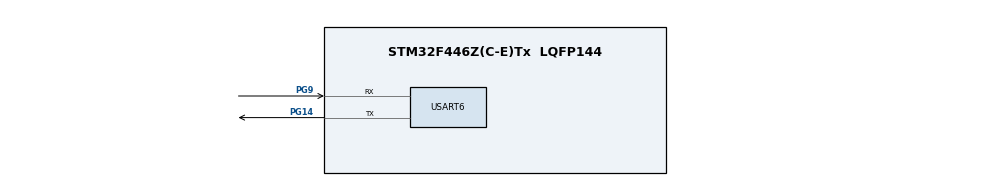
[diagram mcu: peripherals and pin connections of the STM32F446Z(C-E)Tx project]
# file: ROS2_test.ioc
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Dma.Request0=USART6_RX
Dma.Request1=USART6_TX
Dma.USART6_RX.0.Direction=DMA_PERIPH_TO_MEMORY
Dma.USART6_RX.0.FIFOMode=DMA_FIFOMODE_DISABLE
Dma.USART6_RX.0.Instance=DMA2_Stream1
Dma.USART6_RX.0.MemDataAlignment=DMA_MDATAALIGN_BYTE
Dma.USART6_RX.0.MemInc=DMA_MINC_ENABLE
Dma.USART6_RX.0.Mode=DMA_CIRCULAR
Dma.USART6_RX.0.PeriphDataAlignment=DMA_PDATAALIGN_BYTE
Dma.USART6_RX.0.PeriphInc=DMA_PINC_DISABLE
Dma.USART6_RX.0.Priority=DMA_PRIORITY_VERY_HIGH
Dma.USART6_TX.1.Direction=DMA_MEMORY_TO_PERIPH
Dma.USART6_TX.1.FIFOMode=DMA_FIFOMODE_DISABLE
Dma.USART6_TX.1.Instance=DMA2_Stream6
Dma.USART6_TX.1.MemDataAlignment=DMA_MDATAALIGN_BYTE
Dma.USART6_TX.1.MemInc=DMA_MINC_ENABLE
Dma.USART6_TX.1.Mode=DMA_NORMAL
Dma.USART6_TX.1.PeriphDataAlignment=DMA_PDATAALIGN_BYTE
Dma.USART6_TX.1.PeriphInc=DMA_PINC_DISABLE
Dma.USART6_TX.1.Priority=DMA_PRIORITY_VERY_HIGH
FREERTOS.Tasks01=defaultTask,24,3000,StartDefaultTask,Default,NULL,Dynamic,NULL,NULL
Mcu.Family=STM32F4
Mcu.Name=STM32F446Z(C-E)Tx
Mcu.Package=LQFP144
NVIC.DMA2_Stream1_IRQn=true\:5\:0\:false\:false\:true\:true\:false\:true\:true
NVIC.DMA2_Stream6_IRQn=true\:5\:0\:false\:false\:true\:true\:false\:true\:true
NVIC.PriorityGroup=NVIC_PRIORITYGROUP_4
NVIC.TIM1_UP_TIM10_IRQn=true\:15\:0\:false\:false\:true\:false\:false\:true\:true
NVIC.TimeBase=TIM1_UP_TIM10_IRQn
NVIC.TimeBaseIP=TIM1
NVIC.USART6_IRQn=true\:5\:0\:false\:false\:true\:true\:true\:true\:true
PG14.Mode=Asynchronous
PG14.Signal=USART6_TX
PG9.Mode=Asynchronous
PG9.Signal=USART6_RX
PH0-OSC_IN.Mode=HSE-External-Oscillator
PH0-OSC_IN.Signal=RCC_OSC_IN
PH1-OSC_OUT.Mode=HSE-External-Oscillator
PH1-OSC_OUT.Signal=RCC_OSC_OUT
ProjectManager.HeapSize=0x200
ProjectManager.StackSize=0x400
ProjectManager.TargetToolchain=STM32CubeIDE
RCC.CortexFreq_Value=16000000
RCC.USBFreq_Value=96000000
RCC.VCOOutputFreq_Value=192000000
USART6.VirtualMode=VM_ASYNC
VP_FREERTOS_VS_CMSIS_V2.Mode=CMSIS_V2
VP_SYS_VS_tim1.Mode=TIM1
board=custom

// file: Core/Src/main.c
/* USER CODE BEGIN Header */
/**
  ******************************************************************************
  * @file           : main.c
  * @brief          : Main program body
  ******************************************************************************
  * @attention
  *
  * Copyright (c) 2026 STMicroelectronics.
  * All rights reserved.
  *
  * This software is licensed under terms that can be found in the LICENSE file
  * in the root directory of this software component.
  * If no LICENSE file comes with this software, it is provided AS-IS.
  *
  ******************************************************************************
  */
/* USER CODE END Header */
#include "main.h"
#include "cmsis_os.h"

/* USER CODE BEGIN Includes */
#include <rcl/rcl.h>
#include <rcl/error_handling.h>
#include <rclc/rclc.h>
#include <rclc/executor.h>
#include <uxr/client/transport.h>
#include <rmw_microxrcedds_c/config.h>
#include <rmw_microros/rmw_microros.h>

#include <std_msgs/msg/int32.h>

#include <sys/time.h>
/* USER CODE END Includes */

UART_HandleTypeDef huart6;
DMA_HandleTypeDef hdma_usart6_rx;
DMA_HandleTypeDef hdma_usart6_tx;

/* Definitions for defaultTask */
osThreadId_t defaultTaskHandle;
const osThreadAttr_t defaultTask_attributes = {
  .name = "defaultTask",
  .stack_size = 3000 * 4,
  .priority = (osPriority_t) osPriorityNormal,
};

void SystemClock_Config(void);
static void MX_GPIO_Init(void);
static void MX_DMA_Init(void);
static void MX_USART6_UART_Init(void);
void StartDefaultTask(void *argument);

/* USER CODE BEGIN 0 */

/* Variable to monitor incoming data in STM32CubeIDE Live Expressions */
volatile int32_t last_received_msg_data = 0;

/* USER CODE END 0 */

int main(void)
{

  /* MCU Configuration--------------------------------------------------------*/

  /* Reset of all peripherals, Initializes the Flash interface and the Systick. */
  HAL_Init();

  /* Configure the system clock */
  SystemClock_Config();

  /* Initialize all configured peripherals */
  MX_GPIO_Init();
  MX_DMA_Init();
  MX_USART6_UART_Init();

  /* Init scheduler */
  osKernelInitialize();

  /* Create the thread(s) */
  /* creation of defaultTask */
  defaultTaskHandle = osThreadNew(StartDefaultTask, NULL, &defaultTask_attributes);

  /* Start scheduler */
  osKernelStart();

  /* We should never get here as control is now taken by the scheduler */

  /* Infinite loop */
  while (1)
  {

  }
}

void SystemClock_Config(void)
{
  RCC_OscInitTypeDef RCC_OscInitStruct = {0};
  RCC_ClkInitTypeDef RCC_ClkInitStruct = {0};

  /** Configure the main internal regulator output voltage
  */
  __HAL_RCC_PWR_CLK_ENABLE();
  __HAL_PWR_VOLTAGESCALING_CONFIG(PWR_REGULATOR_VOLTAGE_SCALE3);

  /** Initializes the RCC Oscillators according to the specified parameters
  * in the RCC_OscInitTypeDef structure.
  */
  RCC_OscInitStruct.OscillatorType = RCC_OSCILLATORTYPE_HSI;
  RCC_OscInitStruct.HSIState = RCC_HSI_ON;
  RCC_OscInitStruct.HSICalibrationValue = RCC_HSICALIBRATION_DEFAULT;
  RCC_OscInitStruct.PLL.PLLState = RCC_PLL_NONE;
  if (HAL_RCC_OscConfig(&RCC_OscInitStruct) != HAL_OK)
  {
    Error_Handler();
  }

  /** Initializes the CPU, AHB and APB buses clocks
  */
  RCC_ClkInitStruct.ClockType = RCC_CLOCKTYPE_HCLK|RCC_CLOCKTYPE_SYSCLK
                              |RCC_CLOCKTYPE_PCLK1|RCC_CLOCKTYPE_PCLK2;
  RCC_ClkInitStruct.SYSCLKSource = RCC_SYSCLKSOURCE_HSI;
  RCC_ClkInitStruct.AHBCLKDivider = RCC_SYSCLK_DIV1;
  RCC_ClkInitStruct.APB1CLKDivider = RCC_HCLK_DIV1;
  RCC_ClkInitStruct.APB2CLKDivider = RCC_HCLK_DIV1;

  if (HAL_RCC_ClockConfig(&RCC_ClkInitStruct, FLASH_LATENCY_0) != HAL_OK)
  {
    Error_Handler();
  }
}

static void MX_USART6_UART_Init(void)
{

  huart6.Instance = USART6;
  huart6.Init.BaudRate = 115200;
  huart6.Init.WordLength = UART_WORDLENGTH_8B;
  huart6.Init.StopBits = UART_STOPBITS_1;
  huart6.Init.Parity = UART_PARITY_NONE;
  huart6.Init.Mode = UART_MODE_TX_RX;
  huart6.Init.HwFlowCtl = UART_HWCONTROL_NONE;
  huart6.Init.OverSampling = UART_OVERSAMPLING_16;
  if (HAL_UART_Init(&huart6) != HAL_OK)
  {
    Error_Handler();
  }

}

static void MX_DMA_Init(void)
{

  /* DMA controller clock enable */
  __HAL_RCC_DMA2_CLK_ENABLE();

  /* DMA interrupt init */
  /* DMA2_Stream1_IRQn interrupt configuration */
  HAL_NVIC_SetPriority(DMA2_Stream1_IRQn, 5, 0);
  HAL_NVIC_EnableIRQ(DMA2_Stream1_IRQn);
  /* DMA2_Stream6_IRQn interrupt configuration */
  HAL_NVIC_SetPriority(DMA2_Stream6_IRQn, 5, 0);
  HAL_NVIC_EnableIRQ(DMA2_Stream6_IRQn);

}

static void MX_GPIO_Init(void)
{

  /* GPIO Ports Clock Enable */
  __HAL_RCC_GPIOH_CLK_ENABLE();
  __HAL_RCC_GPIOG_CLK_ENABLE();

}

/* USER CODE BEGIN 4 */
bool cubemx_transport_open(struct uxrCustomTransport * transport);
bool cubemx_transport_close(struct uxrCustomTransport * transport);
size_t cubemx_transport_write(struct uxrCustomTransport* transport, const uint8_t * buf, size_t len, uint8_t * err);
size_t cubemx_transport_read(struct uxrCustomTransport* transport, uint8_t* buf, size_t len, int timeout, uint8_t* err);

void * microros_allocate(size_t size, void * state);
void microros_deallocate(void * pointer, void * state);
void * microros_reallocate(void * pointer, size_t size, void * state);
void * microros_zero_allocate(size_t number_of_elements, size_t size_of_element, void * state);

// Subscriber callback
void subscription_callback(const void * msgin)
{
  // Cast received message to the proper type
  const std_msgs__msg__Int32 * msg = (const std_msgs__msg__Int32 *)msgin;

  // Store the received data to our global variable for debugging
  last_received_msg_data = msg->data;

  // You can also use printf here if ITM/UART redirection is configured
  // printf("Received: %d\n", (int)msg->data);
}

// Dummy implementation of _gettimeofday for micro-ROS/Newlib
int _gettimeofday(struct timeval *tv, void *tzvp)
{
    // Use HAL_GetTick() to provide a basic time reference (returns milliseconds)
    uint32_t tick = HAL_GetTick();

    if (tv != NULL) {
        tv->tv_sec = tick / 1000;
        tv->tv_usec = (tick % 1000) * 1000;
    }

    return 0;  // return 0 to indicate success
}

/* USER CODE END 4 */

void StartDefaultTask(void *argument)
{
  /* USER CODE BEGIN 5 */
	// micro-ROS configuration

  rmw_uros_set_custom_transport(
	true,
	(void *) &huart6,
	cubemx_transport_open,
	cubemx_transport_close,
	cubemx_transport_write,
	cubemx_transport_read);

  rcl_allocator_t freeRTOS_allocator = rcutils_get_zero_initialized_allocator();
  freeRTOS_allocator.allocate = microros_allocate;
  freeRTOS_allocator.deallocate = microros_deallocate;
  freeRTOS_allocator.reallocate = microros_reallocate;
  freeRTOS_allocator.zero_allocate =  microros_zero_allocate;

  if (!rcutils_set_default_allocator(&freeRTOS_allocator)) {
	  printf("Error on default allocators (line %d)\n", __LINE__);
  }

  // micro-ROS app

  rcl_publisher_t publisher;
  std_msgs__msg__Int32 msg;

  rcl_subscription_t subscriber;
  std_msgs__msg__Int32 sub_msg;

  rclc_executor_t executor;

  rclc_support_t support;
  rcl_allocator_t allocator;
  rcl_node_t node;

  allocator = rcl_get_default_allocator();

  //create init_options
  rclc_support_init(&support, 0, NULL, &allocator);

  // create node
  rclc_node_init_default(&node, "cubemx_node", "", &support);

  // create publisher
  rclc_publisher_init_default(
	&publisher,
	&node,
	ROSIDL_GET_MSG_TYPE_SUPPORT(std_msgs, msg, Int32),
	"cubemx_publisher");

  // create subscriber
	rclc_subscription_init_default(
	  &subscriber,
	  &node,
	  ROSIDL_GET_MSG_TYPE_SUPPORT(std_msgs, msg, Int32),
	  "cubemx_subscriber");

	// create executor (1 handle needed for the subscriber)
	rclc_executor_init(&executor, &support.context, 1, &allocator);
	rclc_executor_add_subscription(&executor, &subscriber, &sub_msg, &subscription_callback, ON_NEW_DATA);

  msg.data = 0;
  /* Infinite loop */
  for(;;)
	{
	  rcl_ret_t ret = rcl_publish(&publisher, &msg, NULL);
	  if (ret != RCL_RET_OK)
	  {
		printf("Error publishing (line %d)\n", __LINE__);
	  }

	  msg.data++;

	  rclc_executor_spin_some(&executor, 10000000);
	  osDelay(10);
	}
  /* USER CODE END 5 */
}

void HAL_TIM_PeriodElapsedCallback(TIM_HandleTypeDef *htim)
{
  if (htim->Instance == TIM1)
  {
    HAL_IncTick();
  }
}

void Error_Handler(void)
{
  __disable_irq();
  while (1)
  {
  }
}
